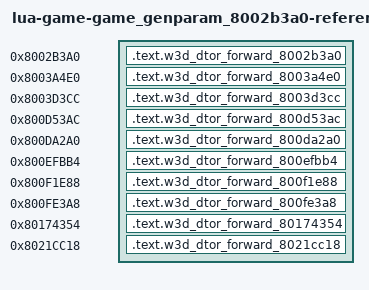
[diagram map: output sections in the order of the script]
/* Generated reference-only placements. All bodies are source-built. */
OUTPUT_FORMAT("elf32-powerpc")
OUTPUT_ARCH(powerpc)
ENTRY(w3d_dtor_forward_8002b3a0)
_SDA_BASE_ = 0x804b2540;
_SDA2_BASE_ = 0x804c2540;
fn_8002a978 = 0x8002a978;
fn_8015ff2c = 0x8015ff2c;
fn_801628ec = 0x801628ec;
fn_80190384 = 0x80190384;
w3d_vtable_8040e368 = 0x8040e368;
w3d_vtable_8040e6d8 = 0x8040e6d8;
w3d_vtable_8040e878 = 0x8040e878;
w3d_vtable_8040fcc8 = 0x8040fcc8;
w3d_vtable_8040fe00 = 0x8040fe00;
w3d_vtable_804102a8 = 0x804102a8;
w3d_vtable_804103a8 = 0x804103a8;
w3d_vtable_80410560 = 0x80410560;
w3d_vtable_80412120 = 0x80412120;
w3d_vtable_80419cb0 = 0x80419cb0;
SECTIONS {
  .text.w3d_dtor_forward_8002b3a0 0x8002b3a0 : { *(.text.w3d_dtor_forward_8002b3a0) }
  .text.w3d_dtor_forward_8003a4e0 0x8003a4e0 : { *(.text.w3d_dtor_forward_8003a4e0) }
  .text.w3d_dtor_forward_8003d3cc 0x8003d3cc : { *(.text.w3d_dtor_forward_8003d3cc) }
  .text.w3d_dtor_forward_800d53ac 0x800d53ac : { *(.text.w3d_dtor_forward_800d53ac) }
  .text.w3d_dtor_forward_800da2a0 0x800da2a0 : { *(.text.w3d_dtor_forward_800da2a0) }
  .text.w3d_dtor_forward_800efbb4 0x800efbb4 : { *(.text.w3d_dtor_forward_800efbb4) }
  .text.w3d_dtor_forward_800f1e88 0x800f1e88 : { *(.text.w3d_dtor_forward_800f1e88) }
  .text.w3d_dtor_forward_800fe3a8 0x800fe3a8 : { *(.text.w3d_dtor_forward_800fe3a8) }
  .text.w3d_dtor_forward_80174354 0x80174354 : { *(.text.w3d_dtor_forward_80174354) }
  .text.w3d_dtor_forward_8021cc18 0x8021cc18 : { *(.text.w3d_dtor_forward_8021cc18) }
  /DISCARD/ : { *(.text*) *(.rodata*) *(.data*) *(.bss*) *(.sdata*) *(.sbss*) *(.comment) }
}
